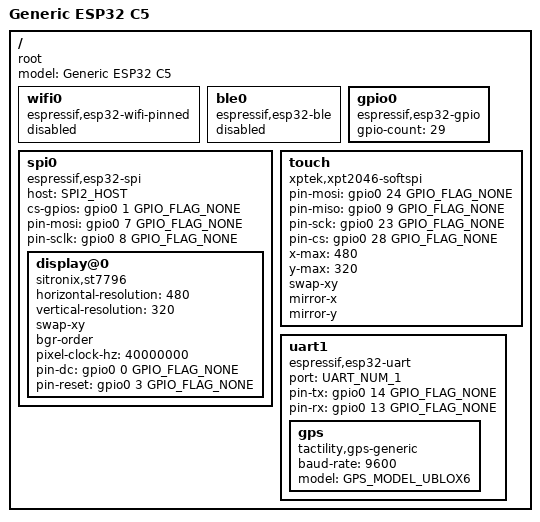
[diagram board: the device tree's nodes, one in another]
/dts-v1/;

#include <tactility/bindings/root.h>
#include <tactility/bindings/esp32_ble.h>
#include <tactility/bindings/esp32_wifi_pinned.h>
#include <tactility/bindings/esp32_gpio.h>
#include <tactility/bindings/esp32_i2c.h>
#include <tactility/bindings/esp32_spi.h>
#include <tactility/bindings/esp32_uart.h>
#include <bindings/st7796.h>
#include <bindings/xpt2046_softspi.h>
#include <gps_generic/bindings.h>

/ {
	compatible = "root";
	model = "Generic ESP32 C5";

	wifi0 {
		compatible = "espressif,esp32-wifi-pinned";
		status = "disabled";
	};

	ble0 {
		compatible = "espressif,esp32-ble";
		status = "disabled";
	};

	gpio0 {
		compatible = "espressif,esp32-gpio";
		gpio-count = <29>;
	};

	spi0 {
		compatible = "espressif,esp32-spi";
		host = <SPI2_HOST>;
		cs-gpios = <&gpio0 1 GPIO_FLAG_NONE>;
		pin-mosi = <&gpio0 7 GPIO_FLAG_NONE>;
		pin-sclk = <&gpio0 8 GPIO_FLAG_NONE>;

		display@0 {
			compatible = "sitronix,st7796";
			horizontal-resolution = <480>;
			vertical-resolution = <320>;
			swap-xy;
			// This panel is wired BGR: LVGL renders RGB565, so without bgr-order the
			// controller reads it with R and B swapped and the screen shows colors
			// reversed (a blue primary renders as yellow-orange). bgr-order sets
			// rgb_ele_order=BGR so the panel interprets the pixel channels correctly.
			bgr-order;
			pixel-clock-hz = <40000000>;
			pin-dc = <&gpio0 0 GPIO_FLAG_NONE>;
			pin-reset = <&gpio0 3 GPIO_FLAG_NONE>;
		};
	};

	/*
	 * T_DIN originally landed on GPIO 15, which is MSPI_IOMUX_PIN_NUM_CS1 - the ESP32-C5 PSRAM
	 * chip select. This driver bit-bangs T_DIN, and driving GPIO 15 detaches PSRAM, so the board
	 * died later inside the allocator; that was the cause of the early boot panics here. GPIO 15
	 * is IOMUX-only and cannot be rerouted through the GPIO matrix, so the wire itself had to be
	 * moved - it is now on GPIO 24. The driver refuses any MSPI pin outright so a regression
	 * names itself instead of panicking somewhere unrelated.
	 *
	 * miso/sck/cs are the board's original values and were corroborated by a bit-banged sweep,
	 * but that sweep ran while GPIO 15 was still disturbing the MSPI bus, so treat them as
	 * probable rather than proven. T_IRQ was independently observed on GPIO 26 (tracked a
	 * physical press cleanly); this driver polls and does not use it.
	 *
	 * Not yet confirmed: that the panel reports coordinates under an actual press. Boot is clean
	 * and the device binds, but touch response has not been observed on hardware.
	 */
	touch {
		compatible = "xptek,xpt2046-softspi";
		pin-mosi = <&gpio0 24 GPIO_FLAG_NONE>; // T_DIN, rewired off GPIO 15 (PSRAM chip select)
		pin-miso = <&gpio0 9 GPIO_FLAG_NONE>;
		pin-sck = <&gpio0 23 GPIO_FLAG_NONE>;
		pin-cs = <&gpio0 28 GPIO_FLAG_NONE>;
		x-max = <480>;
		y-max = <320>;
		swap-xy;
		mirror-x;
		mirror-y;
	};

	/*
	 * NEO-6M on UART1: this side's RX is GPIO 13, so the module's TX lands there, and this
	 * side's TX is GPIO 14, which goes to the module's RX. Cross the wires: module TX -> 13,
	 * module RX -> 14.
	 *
	 * GPIO 11 and 12 are NOT available: they are UART0, the console. IDF's soc/esp32c5/
	 * uart_pins.h defines U0TXD_GPIO_NUM 11 and U0RXD_GPIO_NUM 12, the boot banner prints
	 * "GPIO 12 and 11 are used as console UART I/O pins", and COM11 on the host is a CH343
	 * USB-UART bridge wired to those two pins. Putting UART1 TX on GPIO 11 stops the console
	 * dead at the moment uart_open() takes the pin - it is not a soft failure, the log just ends.
	 *
	 * GPIO 15-22 are the MSPI group (spi_pins.h: CS1 15, CS0 16, MISO 17, WP 18, HD 20, CLK 21,
	 * MOSI 22) and are IOMUX-only, so they are off-limits; esp32_gpio_is_mspi_pin() rejects them
	 * outright. 0,1,3,7,8 drive the display, 9,23,24,26,28 the touch panel. That leaves
	 * 2, 4, 5, 6, 10, 13, 14, 19, 25 and 27; 13 and 14 are the native USB pads, which are free
	 * here because the console is a UART bridge rather than USB-Serial-JTAG.
	 *
	 * A "GPIO n is not usable, maybe used by others" warning on the TX pin is expected and
	 * harmless: the UART driver acquires the pin as a GPIO output first, and IDF's uart_set_pin()
	 * then reports it as already reserved. It is not evidence that the pin is unavailable.
	 *
	 * The NEO-6M is a u-blox 6 part speaking NMEA at 9600 by default. The model is named rather
	 * than left to autoprobe, so a wiring fault reports as a missing device instead of as an
	 * unrecognised chipset.
	 */
	uart1 {
		compatible = "espressif,esp32-uart";
		port = <UART_NUM_1>;
		pin-tx = <&gpio0 14 GPIO_FLAG_NONE>;
		pin-rx = <&gpio0 13 GPIO_FLAG_NONE>;

		gps {
			compatible = "tactility,gps-generic";
			baud-rate = <9600>;
			model = <GPS_MODEL_UBLOX6>;
		};
	};
};
